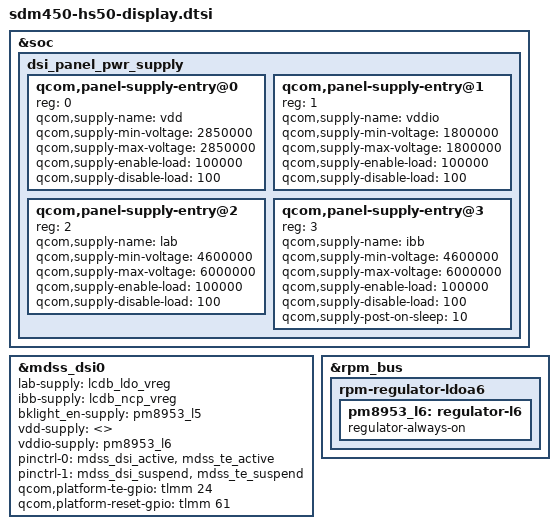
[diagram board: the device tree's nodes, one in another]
/*HS50 code for SR-QL3095-01-71 by gaozhengwei at 2020/07/23 start*/
/*HS50 code for SR-QL3095-01-102 by gaozhengwei at 2020/07/25 start*/
#include "dsi-panel-hx83104a-hd-default_video.dtsi"
#include "dsi-panel-liansi-panda-ili9882h-720p-video.dtsi"
#include "dsi-panel-chuangwei-panda-ili9882h-720p-video.dtsi"
/*HS50 code for SR-QL3095-01-102 by gaozhengwei at 2020/07/25 end*/
/*HS50 code for SR-QL3095-01-370 by gaozhengwei at 2020/08/01 start*/
#include "dsi-panel-truly-truly-nt3652bh-720p-video.dtsi"
/*HS50 code for SR-QL3095-01-370 by gaozhengwei at 2020/08/01 end*/
/*HS50 code for SR-QL3095-01-719 by fengzhigang at 2020/09/03 start*/
#include "dsi-panel-txd-qc-ili9882n-720p-video.dtsi"
/*HS50 code for SR-QL3095-01-719 by fengzhigang at 2020/09/03 end*/
/*HS50 code for SR-QL3095-01-831 by fengzhigang at 2020/10/26 start*/
#include "dsi-panel-txd-inx-hx83102d-swid51-720p-video.dtsi"
/*HS50 code for SR-QL3095-01-831 by fengzhigang at 2020/10/26 end*/
/*HS50 code for SR-QL3095-01-71 by gaozhengwei at 2020/08/03 start*/
#include "dsi-panel-liansi-mdt-ili9882n-720p-video.dtsi"
/*HS50 code for SR-QL3095-01-71 by gaozhengwei at 2020/08/03 end*/
/*HS50 code for SR-QL3095-01-767 by gaozhengwei at 2020/09/01 start*/
#include "dsi-panel-gx-boe-hx83102d-7mask-720p-video.dtsi"
/*HS50 code for SR-QL3095-01-735 by fengzhigang at 2020/10/10 start*/
#include "dsi-panel-gx-boe-6mask-hx83102d-720p-video.dtsi"
/*HS50 code for SR-QL3095-01-735 by fengzhigang at 2020/10/10 end*/
/*HS50 code for SR-QL3095-01-767 by gaozhengwei at 2020/09/01 end*/
/*HS50 code for HS50-1707 by gaozhengwei at 2020/09/14 start*/
#include "dsi-panel-liansi-panda-lrpol-ili9882h-720p-video.dtsi"
#include "dsi-panel-chuangwei-panda-lrpol-ili9882h-720p-video.dtsi"
/*HS50 code for HS50-1707 by gaozhengwei at 2020/09/14 end*/
/*HS50 code for SR-QL3095-01-743 by fengzhigang at 2020/09/27 start*/
#include "dsi-panel-liansi-panda-ili9882h-swid22-720p-video.dtsi"
/*HS50 code for SR-QL3095-01-743 by fengzhigang at 2020/09/27 end*/
/*HS50 code for SR-QL3095-01-755 by weiqiang at 2020/10/02 start*/
#include "dsi-panel-truly-truly-rs460-nt3652bh-swid41-720p-video.dtsi"
/*HS50 code for SR-QL3095-01-755 by weiqiang at 2020/10/02 end*/
/*HS50 code for SR-QL3095-01-845 by zhaoxiangxiang at 2020/10/16 start*/
#include "dsi-panel-truly-truly-rs460-nl9911c-swid42-720p-video.dtsi"
/*HS50 code for SR-QL3095-01-845 by zhaoxiangxiang at 2020/10/16 end*/
/*HS50 code for SR-QL3095-01-847  by gaozhengwei at 2020/10/27 start*/
#include "dsi-panel-gx-boe-9mask-epd6301-swid62-720p-video.dtsi"
/*HS50 code for SR-QL3095-01-847  by gaozhengwei at 2020/10/27 end*/
/*HS50 code for HS50-4157 by gaozhengwei at 2020/11/07 start*/
#include "dsi-panel-ls-panda-sblpol-ljfpc-ili9882h-swid23-720p-video.dtsi"
/*HS50 code for HS50-4157 by gaozhengwei at 2020/11/07 end*/
/*HS50 code for SR-QL3095-01-871  by liupengtao at 2020/12/1 start*/
#include "dsi-panel-jdd-panda-ili9882h-swid70-720p-video.dtsi"
/*HS50 code for SR-QL3095-01-871  by liupengtao at 2020/12/1 end*/
/*HS50 code for SR-QL3095-01-905  by gaozhengwei at 2020/12/24 start*/
#include "dsi-panel-hlt-boe-ili7806s-swid81-720p-video.dtsi"
/*HS50 code for SR-QL3095-01-905  by gaozhengwei at 2020/12/24 end*/
/*HS50 code for SR-QL3095-01-893 by gaozhengwei at 2020/12/29 start*/
#include "dsi-panel-liansi-boe-9mask-hx83112a-swid24-720p-video.dtsi"
/*HS50 code for SR-QL3095-01-893 by gaozhengwei at 2020/12/29 start*/
/*HS50 code for SR-QL3095-01-907  by fengzhigang at 2021/01/22 start*/
#include "dsi-panel-jz-inx-hx83102d-swid90-720p-video.dtsi"
/*HS50 code for SR-QL3095-01-907  by fengzhigang at 2021/01/22 end*/
/*HS50 code for SR-QL3095-01-927  by fengzhigang at 2021/02/09 start*/
#include "dsi-panel-txd-boe-9mask-ili7806s-swid53-720p-video.dtsi"
/*HS50 code for SR-QL3095-01-927  by fengzhigang at 2021/02/09 end*/
&soc {
	dsi_panel_pwr_supply: dsi_panel_pwr_supply {
		#address-cells = <1>;
		#size-cells = <0>;

		qcom,panel-supply-entry@0 {
			reg = <0>;
			qcom,supply-name = "vdd";
			qcom,supply-min-voltage = <2850000>;
			qcom,supply-max-voltage = <2850000>;
			qcom,supply-enable-load = <100000>;
			qcom,supply-disable-load = <100>;
		};

		qcom,panel-supply-entry@1 {
			reg = <1>;
			qcom,supply-name = "vddio";
			qcom,supply-min-voltage = <1800000>;
			qcom,supply-max-voltage = <1800000>;
			qcom,supply-enable-load = <100000>;
			qcom,supply-disable-load = <100>;
		};
		qcom,panel-supply-entry@2 {
			reg = <2>;
			qcom,supply-name = "lab";
			qcom,supply-min-voltage = <4600000>;
			qcom,supply-max-voltage = <6000000>;
			qcom,supply-enable-load = <100000>;
			qcom,supply-disable-load = <100>;
		};

		qcom,panel-supply-entry@3 {
			reg = <3>;
			qcom,supply-name = "ibb";
			qcom,supply-min-voltage = <4600000>;
			qcom,supply-max-voltage = <6000000>;
			qcom,supply-enable-load = <100000>;
			qcom,supply-disable-load = <100>;
			qcom,supply-post-on-sleep = <10>;
		};
	};
};

&mdss_dsi0 {
	lab-supply = <&lcdb_ldo_vreg>;
	ibb-supply = <&lcdb_ncp_vreg>;
	bklight_en-supply = <&pm8953_l5>;
/*HS50-SR-QL3095-01-137This power supply is for camera AF. if display is not used, delete it.
Otherwise, the camera AF will start up with a constant high voltage added by xuxianwei at 2020/08/13 start*/
	vdd-supply = <>;
/*HS50-SR-QL3095-01-137 This power supply is for camera AF. if display is not used, delete it.
Otherwise, the camera AF will start up with a constant high voltage added by xuxianwei at 2020/08/13 end*/
	vddio-supply = <&pm8953_l6>;

	/delete-property/ qcom,platform-bklight-en-gpio;
	pinctrl-names = "mdss_default", "mdss_sleep";
	pinctrl-0 = <&mdss_dsi_active &mdss_te_active>;
	pinctrl-1 = <&mdss_dsi_suspend &mdss_te_suspend>;
	qcom,platform-te-gpio = <&tlmm 24 0>;
	qcom,platform-reset-gpio = <&tlmm 61 0>;
};

&rpm_bus {
	rpm-regulator-ldoa6 {
		pm8953_l6: regulator-l6 {
			regulator-always-on;
		};
	};
};
/*HS50 code for SR-QL3095-01-71 by gaozhengwei at 2020/07/23 end*/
